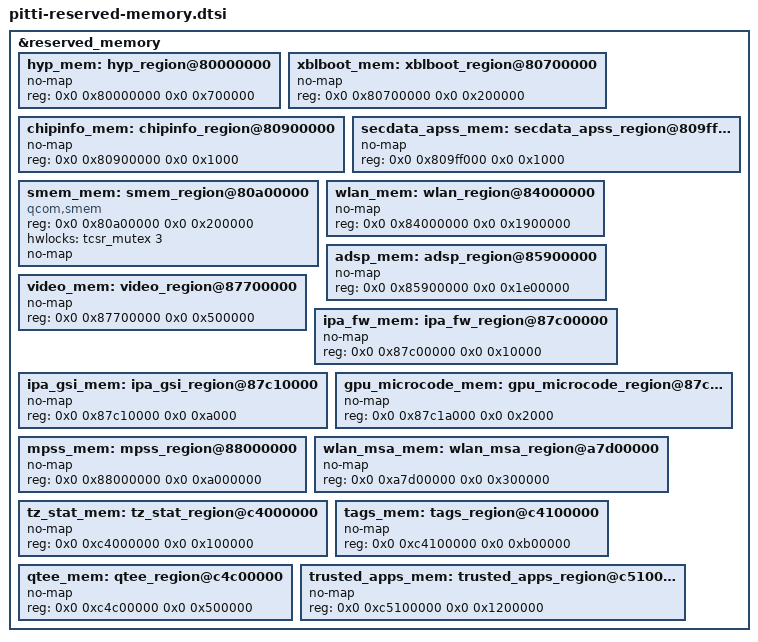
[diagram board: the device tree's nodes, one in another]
&reserved_memory {
	#address-cells = <2>;
	#size-cells = <2>;
	ranges;

	hyp_mem: hyp_region@80000000 {
		no-map;
		reg = <0x0 0x80000000 0x0 0x700000>;
	};

	xblboot_mem: xblboot_region@80700000 {
		no-map;
		reg = <0x0 0x80700000 0x0 0x200000>;
	};

	chipinfo_mem: chipinfo_region@80900000 {
		no-map;
		reg = <0x0 0x80900000 0x0 0x1000>;
	};

	secdata_apss_mem: secdata_apss_region@809ff000 {
		no-map;
		reg = <0x0 0x809ff000 0x0 0x1000>;
	};

	smem_mem: smem_region@80a00000 {
		compatible = "qcom,smem";
		reg = <0x0 0x80a00000 0x0 0x200000>;
		hwlocks = <&tcsr_mutex 3>;
		no-map;
	};

	wlan_mem: wlan_region@84000000 {
		no-map;
		reg = <0x0 0x84000000 0x0 0x1900000>;
	};

	adsp_mem: adsp_region@85900000 {
		no-map;
		reg = <0x0 0x85900000 0x0 0x1e00000>;
	};

	video_mem: video_region@87700000 {
		no-map;
		reg = <0x0 0x87700000 0x0 0x500000>;
	};

	ipa_fw_mem: ipa_fw_region@87c00000 {
		no-map;
		reg = <0x0 0x87c00000 0x0 0x10000>;
	};

	ipa_gsi_mem: ipa_gsi_region@87c10000 {
		no-map;
		reg = <0x0 0x87c10000 0x0 0xa000>;
	};

	gpu_microcode_mem: gpu_microcode_region@87c1a000 {
		no-map;
		reg = <0x0 0x87c1a000 0x0 0x2000>;
	};

	mpss_mem: mpss_region@88000000 {
		no-map;
		reg = <0x0 0x88000000 0x0 0xa000000>;
	};

	/* UEFI region reclaimed by Linux */

	wlan_msa_mem: wlan_msa_region@a7d00000 {
		no-map;
		reg = <0x0 0xa7d00000 0x0 0x300000>;
	};

	/* Linux kernel image is loaded at 0xa8000000 */

	tz_stat_mem: tz_stat_region@c4000000 {
		no-map;
		reg = <0x0 0xc4000000 0x0 0x100000>;
	};

	tags_mem: tags_region@c4100000 {
		no-map;
		reg = <0x0 0xc4100000 0x0 0xb00000>;
	};

	qtee_mem: qtee_region@c4c00000 {
		no-map;
		reg = <0x0 0xc4c00000 0x0 0x500000>;
	};

	trusted_apps_mem: trusted_apps_region@c5100000 {
		no-map;
		reg = <0x0 0xc5100000 0x0 0x1200000>;
	};

};
